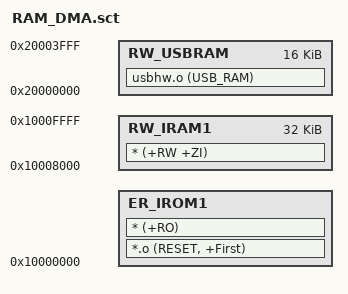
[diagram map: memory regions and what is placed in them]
; *************************************************************
; *** Scatter-Loading Description File generated by uVision ***
; *************************************************************

LR_IROM1 0x10000000 0x00008000  {  ; load region
  ER_IROM1 0x10000000  {           ; load address = execution address
   *.o (RESET, +First)
   * (+RO)
  }
  RW_IRAM1 0x10008000 0x00008000  {  ; RW data
   * (+RW +ZI)
  }
  RW_USBRAM 0x20000000 0x00004000  {
    usbhw.o   (USB_RAM)
  }
}

